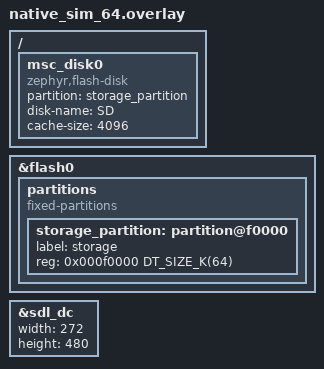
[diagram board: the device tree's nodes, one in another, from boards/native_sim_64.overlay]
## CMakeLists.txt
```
# @file      CMakeLists.txt
# @brief     Rush project CMakeLists file
#
# Copyright (C) Witekio
#
# This file is part of the Zephyr Rush demonstration.
#
# This demonstration is free software: you can redistribute it and/or modify
# it under the terms of the GNU General Public License as published by
# the Free Software Foundation, either version 3 of the License, or
# (at your option) any later version.
#
# This demonstration is distributed in the hope that it will be useful,
# but WITHOUT ANY WARRANTY; without even the implied warranty of
# MERCHANTABILITY or FITNESS FOR A PARTICULAR PURPOSE. See the
# GNU General Public License for more details.
#
# You should have received a copy of the GNU General Public License
# along with This demonstration. If not, see <http://www.gnu.org/licenses/>.

cmake_minimum_required(VERSION 3.20.0)

find_package(Zephyr REQUIRED HINTS $ENV{ZEPHYR_BASE})

project(app LANGUAGES C CXX)

file(GLOB_RECURSE SOURCES "src/*.h" "src/*.c" "src/*.cpp")
target_sources(app PRIVATE ${SOURCES})

target_include_directories(app PRIVATE src)

include(cmake/Version.cmake)
```

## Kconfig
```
# @file      Kconfig
# @brief     Rush project Kconfig file
#
# Copyright (C) Witekio
#
# This file is part of the Zephyr Rush demonstration.
#
# This demonstration is free software: you can redistribute it and/or modify
# it under the terms of the GNU General Public License as published by
# the Free Software Foundation, either version 3 of the License, or
# (at your option) any later version.
#
# This demonstration is distributed in the hope that it will be useful,
# but WITHOUT ANY WARRANTY; without even the implied warranty of
# MERCHANTABILITY or FITNESS FOR A PARTICULAR PURPOSE. See the
# GNU General Public License for more details.
#
# You should have received a copy of the GNU General Public License
# along with This demonstration. If not, see <http://www.gnu.org/licenses/>.

menu "Zephyr"
source "Kconfig.zephyr"
endmenu

menu "Platform"

config PLATFORM_DISPLAY_BLANKING_OFF
    bool "Disable display blanking during initialization"

config PLATFORM_DISPLAY_ROTATION_90
    bool "Enable lvgl runtime display rotation"

endmenu
```

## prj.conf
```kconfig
# @file      prj.conf
# @brief     Rush project configuration file
#
# Copyright (C) Witekio
#
# This file is part of the Zephyr Rush demonstration.
#
# This demonstration is free software: you can redistribute it and/or modify
# it under the terms of the GNU General Public License as published by
# the Free Software Foundation, either version 3 of the License, or
# (at your option) any later version.
#
# This demonstration is distributed in the hope that it will be useful,
# but WITHOUT ANY WARRANTY; without even the implied warranty of
# MERCHANTABILITY or FITNESS FOR A PARTICULAR PURPOSE. See the
# GNU General Public License for more details.
#
# You should have received a copy of the GNU General Public License
# along with This demonstration. If not, see <http://www.gnu.org/licenses/>.

# General
CONFIG_GPIO=y
CONFIG_DISPLAY=y
CONFIG_CONSOLE=y
CONFIG_LOG=y
CONFIG_REQUIRES_FLOAT_PRINTF=y

# System
CONFIG_MAIN_STACK_SIZE=65536
CONFIG_HEAP_MEM_POOL_SIZE=16384
CONFIG_SYSTEM_WORKQUEUE_STACK_SIZE=16384

# Entropy
CONFIG_ENTROPY_GENERATOR=y
CONFIG_ENTROPY_DEVICE_RANDOM_GENERATOR=y

# Input
CONFIG_INPUT=y
CONFIG_INPUT_THREAD_PRIORITY_OVERRIDE=y
CONFIG_INPUT_THREAD_PRIORITY=0
CONFIG_INPUT_QUEUE_MAX_MSGS=64

# C++
CONFIG_CPP=y
CONFIG_STD_CPP23=y
CONFIG_REQUIRES_FULL_LIBCPP=y

# LVGL
CONFIG_LVGL=y
CONFIG_LV_Z_MEM_POOL_SIZE=327680
CONFIG_LV_COLOR_DEPTH_32=y
CONFIG_LV_Z_VDB_SIZE=100
CONFIG_LV_Z_DOUBLE_VDB=y
CONFIG_LV_Z_POINTER_INPUT=y

# TFlite Micro
CONFIG_TENSORFLOW_LITE_MICRO=y

# File system
CONFIG_FILE_SYSTEM=y
CONFIG_FAT_FILESYSTEM_ELM=y
```

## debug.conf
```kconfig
# @file      debug.conf
# @brief     Rush project debug configuration file
#
# Copyright (C) Witekio
#
# This file is part of the Zephyr Rush demonstration.
#
# This demonstration is free software: you can redistribute it and/or modify
# it under the terms of the GNU General Public License as published by
# the Free Software Foundation, either version 3 of the License, or
# (at your option) any later version.
#
# This demonstration is distributed in the hope that it will be useful,
# but WITHOUT ANY WARRANTY; without even the implied warranty of
# MERCHANTABILITY or FITNESS FOR A PARTICULAR PURPOSE. See the
# GNU General Public License for more details.
#
# You should have received a copy of the GNU General Public License
# along with This demonstration. If not, see <http://www.gnu.org/licenses/>.

CONFIG_LOG=y
CONFIG_LOG_MODE_IMMEDIATE=y
CONFIG_LOG_DEFAULT_LEVEL=3

CONFIG_ASSERT=y
CONFIG_DEBUG=y

CONFIG_INIT_STACKS=y
CONFIG_THREAD_STACK_INFO=y
CONFIG_STACK_SENTINEL=y
CONFIG_STACK_USAGE=y

CONFIG_SYS_HEAP_RUNTIME_STATS=y

CONFIG_LV_USE_LOG=y
CONFIG_LV_LOG_LEVEL_WARN=y

CONFIG_THREAD_NAME=y

CONFIG_LV_USE_ASSERT_OBJ=y
CONFIG_LV_USE_ASSERT_MEM_INTEGRITY=y
CONFIG_LV_USE_ASSERT_NULL=y
CONFIG_LV_USE_ASSERT_STYLE=y
CONFIG_LV_USE_ASSERT_MALLOC=y
```

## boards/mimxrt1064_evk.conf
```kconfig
# @file      mimxrt1064_evk.conf
# @brief     mimxrt1064_evk board configuration file overlay
#
# Copyright (C) Witekio
#
# This file is part of the Zephyr Rush demonstration.
#
# This demonstration is free software: you can redistribute it and/or modify
# it under the terms of the GNU General Public License as published by
# the Free Software Foundation, either version 3 of the License, or
# (at your option) any later version.
#
# This demonstration is distributed in the hope that it will be useful,
# but WITHOUT ANY WARRANTY; without even the implied warranty of
# MERCHANTABILITY or FITNESS FOR A PARTICULAR PURPOSE. See the
# GNU General Public License for more details.
#
# You should have received a copy of the GNU General Public License
# along with This demonstration. If not, see <http://www.gnu.org/licenses/>.

# General
CONFIG_COMMON_LIBC_MALLOC_ARENA_SIZE=16384
CONFIG_UART_CONSOLE=y

# SD Card
CONFIG_SDHC=y
CONFIG_DISK_DRIVER_SDMMC=y

# Display
CONFIG_DISPLAY_MCUX_ELCDIF=y
CONFIG_MCUX_ELCDIF_FB_NUM=1
CONFIG_MCUX_ELCDIF_FB_SIZE=522240

# Display rotation
CONFIG_DMA=y
CONFIG_MCUX_PXP=y
CONFIG_MCUX_ELCDIF_PXP=y
CONFIG_MCUX_ELCDIF_PXP_ROTATE_270=y

# App
CONFIG_PLATFORM_DISPLAY_ROTATION_90=y
```

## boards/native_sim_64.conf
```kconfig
# @file      native_sim_64.conf
# @brief     native_sim_64 board configuration file overlay
#
# Copyright (C) Witekio
#
# This file is part of the Zephyr Rush demonstration.
#
# This demonstration is free software: you can redistribute it and/or modify
# it under the terms of the GNU General Public License as published by
# the Free Software Foundation, either version 3 of the License, or
# (at your option) any later version.
#
# This demonstration is distributed in the hope that it will be useful,
# but WITHOUT ANY WARRANTY; without even the implied warranty of
# MERCHANTABILITY or FITNESS FOR A PARTICULAR PURPOSE. See the
# GNU General Public License for more details.
#
# You should have received a copy of the GNU General Public License
# along with This demonstration. If not, see <http://www.gnu.org/licenses/>.

# App
CONFIG_PLATFORM_DISPLAY_BLANKING_OFF=y
```

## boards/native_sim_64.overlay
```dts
/**
 * @file      native_sim_64.overlay
 * @brief     native_sim_64 board project overlay
 *
 * Copyright (C) Witekio
 *
 * This file is part of the Zephyr Rush demonstration.
 *
 * This demonstration is free software: you can redistribute it and/or modify
 * it under the terms of the GNU General Public License as published by
 * the Free Software Foundation, either version 3 of the License, or
 * (at your option) any later version.
 *
 * This demonstration is distributed in the hope that it will be useful,
 * but WITHOUT ANY WARRANTY; without even the implied warranty of
 * MERCHANTABILITY or FITNESS FOR A PARTICULAR PURPOSE. See the
 * GNU General Public License for more details.
 *
 * You should have received a copy of the GNU General Public License
 * along with This demonstration. If not, see <http://www.gnu.org/licenses/>.
 */


/delete-node/ &storage_partition;

&flash0 {
	partitions {
		compatible = "fixed-partitions";
		#address-cells = <1>;
		#size-cells = <1>;

		storage_partition: partition@f0000 {
			label = "storage";
			reg = <0x000f0000 DT_SIZE_K(64)>;
		};
	};
};

/ {
	msc_disk0 {
		status = "okay";
		compatible = "zephyr,flash-disk";
		partition = <&storage_partition>;
		disk-name = "SD";
		cache-size = <4096>;
	};
};

&sdl_dc {
    width = <272>;
    height = <480>;
};
```

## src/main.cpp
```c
/**
 * @file      main.cpp
 * @brief     Main entry point
 *
 * Copyright (C) Witekio
 *
 * This file is part of the Zephyr Rush demonstration.
 *
 * This demonstration is free software: you can redistribute it and/or modify
 * it under the terms of the GNU General Public License as published by
 * the Free Software Foundation, either version 3 of the License, or
 * (at your option) any later version.
 *
 * This demonstration is distributed in the hope that it will be useful,
 * but WITHOUT ANY WARRANTY; without even the implied warranty of
 * MERCHANTABILITY or FITNESS FOR A PARTICULAR PURPOSE. See the
 * GNU General Public License for more details.
 *
 * You should have received a copy of the GNU General Public License
 * along with This demonstration. If not, see <http://www.gnu.org/licenses/>.
 */

#include "Platform/Zephyr/FS.h"
#include "Platform/Zephyr/Platform.h"
#include "UI/App.h"

static App app;

i32 main() {
    Platform::Init();
    Platform::FS::Init();

    app.Run();
}
```
